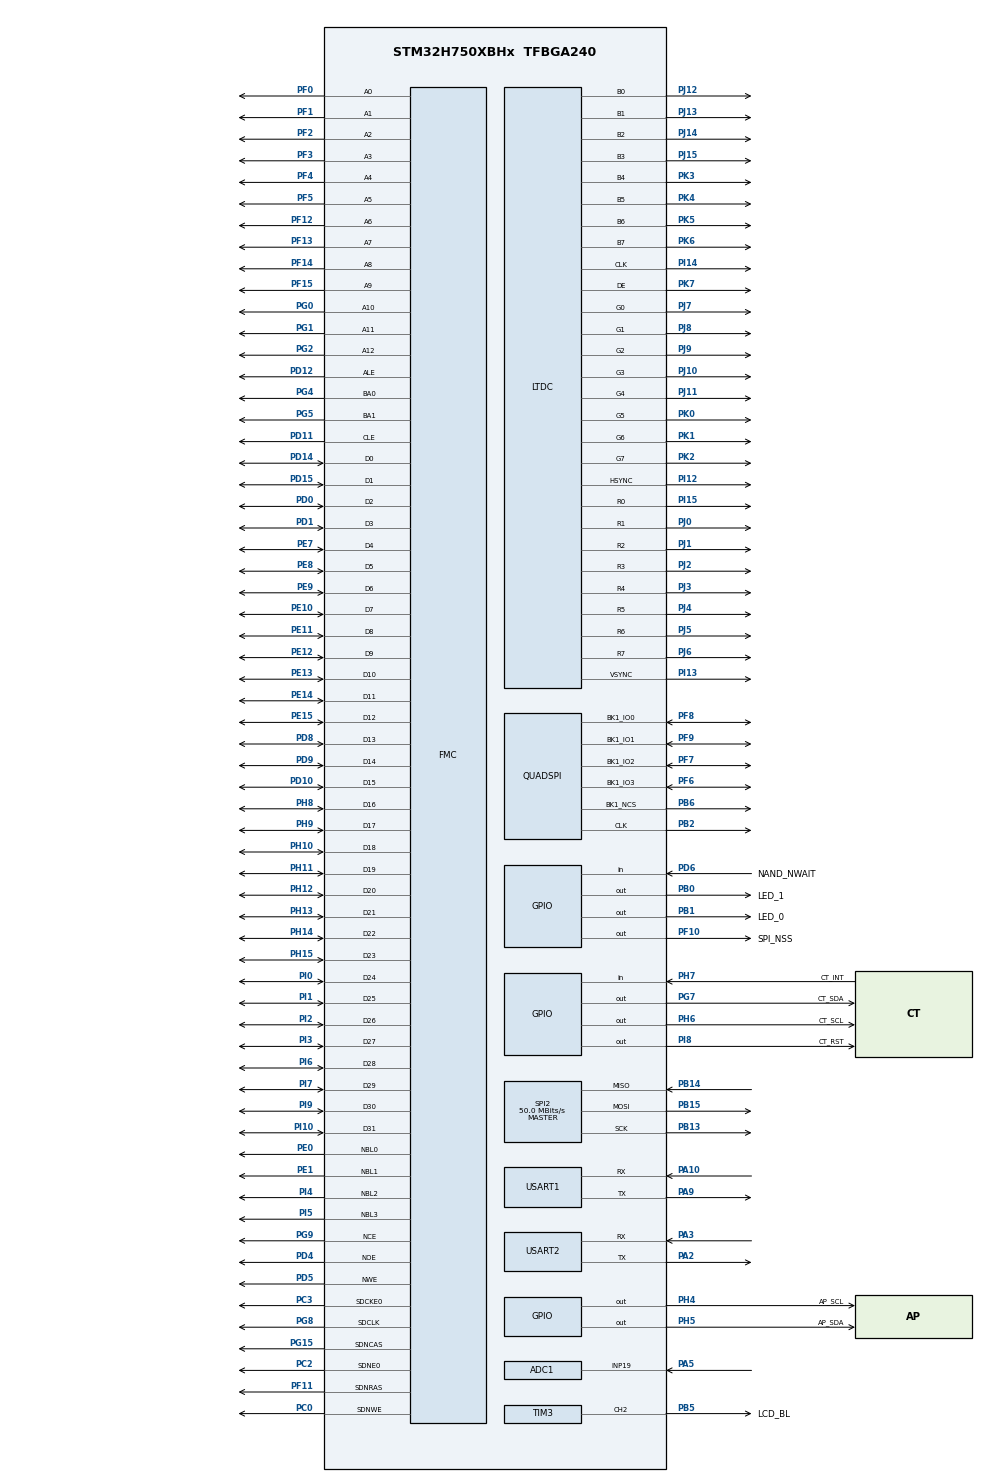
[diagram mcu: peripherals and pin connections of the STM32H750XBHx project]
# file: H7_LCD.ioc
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ADC1.Channel-0\#ChannelRegularConversion=ADC_CHANNEL_19
ADC1.ContinuousConvMode=DISABLE
ADC1.ConversionDataManagement=ADC_CONVERSIONDATA_DR
ADC1.ExternalTrigConv=ADC_SOFTWARE_START
ADC1.NbrOfConversion=1
ADC1.NbrOfConversionFlag=1
ADC1.OffsetNumber-0\#ChannelRegularConversion=ADC_OFFSET_NONE
ADC1.OffsetSignedSaturation-0\#ChannelRegularConversion=DISABLE
ADC1.Overrun=ADC_OVR_DATA_OVERWRITTEN
ADC1.Rank-0\#ChannelRegularConversion=1
ADC1.SamplingTime-0\#ChannelRegularConversion=ADC_SAMPLETIME_387CYCLES_5
ADC1.master=1
CORTEX_M7.CPU_DCache=Enabled
CORTEX_M7.CPU_ICache=Enabled
DMA2D.Mode=DMA2D_M2M
FATFS._CODE_PAGE=936
FATFS._FS_EXFAT=1
FATFS._FS_LOCK=4
FATFS._FS_NORTC=0
FATFS._LFN_UNICODE=0
FATFS._MAX_SS=512
FATFS._USE_CHMOD=1
FATFS._USE_FIND=1
FATFS._USE_LABEL=1
FATFS._USE_LFN=3
FATFS._VOLUMES=1
FMC.AttributeSpaceHiZSetupTime1=10
FMC.AttributeSpaceHoldSetupTime1=10
FMC.AttributeSpaceSetupTime1=10
FMC.AttributeSpaceWaitSetupTime1=10
FMC.CASLatency1=FMC_SDRAM_CAS_LATENCY_2
FMC.ColumnBitsNumber1=FMC_SDRAM_COLUMN_BITS_NUM_9
FMC.CommonSpaceHiZSetupTime1=10
FMC.CommonSpaceHoldSetupTime1=10
FMC.CommonSpaceSetupTime1=10
FMC.CommonSpaceWaitSetupTime1=10
FMC.ECCPageSize1=FMC_NAND_ECC_PAGE_SIZE_512BYTE
FMC.EccComputation1=FMC_NAND_ECC_DISABLE
FMC.ExitSelfRefreshDelay1=8
FMC.LoadToActiveDelay1=2
FMC.NandBlockNbr1=2048
FMC.NandBlockSize1=64
FMC.NandPageSize1=2048
FMC.NandPlaneNbr1=2
FMC.NandPlaneSize1=4096
FMC.NandSpareAreaSize1=64
FMC.RCDDelay1=2
FMC.RPDelay1=2
FMC.ReadBurst1=FMC_SDRAM_RBURST_ENABLE
FMC.RowCycleDelay1=6
FMC.SDClockPeriod1=FMC_SDRAM_CLOCK_PERIOD_2
FMC.SelfRefreshTime1=6
FMC.TARSetupTime1=10
FMC.TCLRSetupTime1=10
FMC.WriteRecoveryTime1=4
LTDC.ActiveH=480
LTDC.ActiveW=800
LTDC.Alpha_L0=255
LTDC.BlendingFactor1_L0=LTDC_BLENDING_FACTOR1_PAxCA
LTDC.BlendingFactor2_L0=LTDC_BLENDING_FACTOR2_PAxCA
LTDC.Blue=0
LTDC.Blue_L0=0
LTDC.FBStartAdress_L0=0xc0000000
LTDC.FBStartAdress_L1=0xc0177001
LTDC.Green_L0=0
LTDC.HBP=88
LTDC.HFP=40
LTDC.HSync=48
LTDC.ImageHeight_L0=480
LTDC.ImageHeight_L1=480
LTDC.ImageWidth_L0=800
LTDC.Layers=0
LTDC.PCPolarity=LTDC_PCPOLARITY_IPC
LTDC.Red=0
LTDC.VBP=32
LTDC.VFP=13
LTDC.VSync=3
LTDC.WindowX1_L0=800
LTDC.WindowX1_L1=800
LTDC.WindowY1_L0=480
LTDC.WindowY1_L1=480
Mcu.Family=STM32H7
Mcu.Name=STM32H750XBHx
Mcu.Package=TFBGA240
NVIC.DMA2D_IRQn=true\:0\:0\:false\:false\:true\:true\:true\:true
NVIC.LTDC_IRQn=true\:0\:0\:false\:false\:true\:true\:true\:true
NVIC.PriorityGroup=NVIC_PRIORITYGROUP_4
NVIC.TIM3_IRQn=true\:1\:0\:true\:false\:true\:true\:true\:true
NVIC.TIM7_IRQn=true\:0\:0\:false\:false\:true\:true\:true\:true
NVIC.USART2_IRQn=true\:0\:0\:false\:false\:true\:true\:true\:true
PA10.GPIO_Speed=GPIO_SPEED_FREQ_LOW
PA10.Mode=Asynchronous
PA10.PinAttribute=Free
PA10.Signal=USART1_RX
PA13\ (JTMS/SWDIO).Mode=Serial_Wire
PA13\ (JTMS/SWDIO).PinAttribute=Free
PA13\ (JTMS/SWDIO).Signal=DEBUG_JTMS-SWDIO
PA14\ (JTCK/SWCLK).Mode=Serial_Wire
PA14\ (JTCK/SWCLK).PinAttribute=Free
PA14\ (JTCK/SWCLK).Signal=DEBUG_JTCK-SWCLK
PA2.GPIO_Speed=GPIO_SPEED_FREQ_LOW
PA2.Mode=Asynchronous
PA2.PinAttribute=Free
PA2.Signal=USART2_TX
PA3.GPIO_Speed=GPIO_SPEED_FREQ_LOW
PA3.Mode=Asynchronous
PA3.Signal=USART2_RX
PA5.Signal=ADCx_INP19
PA9.GPIO_PuPd=GPIO_NOPULL
PA9.GPIO_Speed=GPIO_SPEED_FREQ_LOW
PA9.Mode=Asynchronous
PA9.PinAttribute=Free
PA9.Signal=USART1_TX
PB0.GPIO_Label=LED_1
PB0.GPIO_PuPd=GPIO_PULLUP
PB0.PinState=GPIO_PIN_SET
PB0.Signal=GPIO_Output
PB1.GPIO_Label=LED_0
PB1.GPIO_PuPd=GPIO_PULLUP
PB1.PinState=GPIO_PIN_SET
PB1.Signal=GPIO_Output
PB13.GPIO_Speed=GPIO_SPEED_FREQ_HIGH
PB13.Mode=Full_Duplex_Master
PB13.Signal=SPI2_SCK
PB14.GPIO_Speed=GPIO_SPEED_FREQ_HIGH
PB14.Mode=Full_Duplex_Master
PB14.Signal=SPI2_MISO
PB15.GPIO_Speed=GPIO_SPEED_FREQ_HIGH
PB15.Mode=Full_Duplex_Master
PB15.Signal=SPI2_MOSI
PB2.GPIO_PuPd=GPIO_PULLUP
PB2.GPIO_Speed=GPIO_SPEED_FREQ_HIGH
PB2.Mode=Single Bank 1
PB2.PinAttribute=Free
PB2.Signal=QUADSPI_CLK
PB5.GPIO_Label=LCD_BL
PB5.GPIO_PuPd=GPIO_PULLUP
PB5.GPIO_Speed=GPIO_SPEED_FREQ_LOW
PB5.Signal=S_TIM3_CH2
PB6.GPIO_FM6=__NULL
PB6.GPIO_PuPd=GPIO_PULLUP
PB6.GPIO_Speed=GPIO_SPEED_FREQ_HIGH
PB6.Mode=Single Bank 1
PB6.PinAttribute=Free
PB6.Signal=QUADSPI_BK1_NCS
PC0.GPIO_PuPd=GPIO_PULLUP
PC0.PinAttribute=Free
PC0.Signal=FMC_SDNWE
PC14-OSC32_IN\ (OSC32_IN).Mode=LSE-External-Oscillator
PC14-OSC32_IN\ (OSC32_IN).PinAttribute=Free
PC14-OSC32_IN\ (OSC32_IN).Signal=RCC_OSC32_IN
PC15-OSC32_OUT\ (OSC32_OUT).Mode=LSE-External-Oscillator
PC15-OSC32_OUT\ (OSC32_OUT).PinAttribute=Free
PC15-OSC32_OUT\ (OSC32_OUT).Signal=RCC_OSC32_OUT
PC2.GPIO_PuPd=GPIO_PULLUP
PC2.Mode=SdramChipSelect1_1
PC2.PinAttribute=Free
PC2.Signal=FMC_SDNE0
PC3.GPIO_PuPd=GPIO_PULLUP
PC3.Mode=SdramChipSelect1_1
PC3.PinAttribute=Free
PC3.Signal=FMC_SDCKE0
PD0.PinAttribute=Free
PD0.Signal=FMC_D2_DA2
PD1.PinAttribute=Free
PD1.Signal=FMC_D3_DA3
PD10.Signal=FMC_D15_DA15
PD11.Signal=FMC_A16_CLE
PD12.Signal=FMC_A17_ALE
PD14.Signal=FMC_D0_DA0
PD15.Signal=FMC_D1_DA1
PD4.PinAttribute=Free
PD4.Signal=FMC_NOE
PD5.PinAttribute=Free
PD5.Signal=FMC_NWE
PD6.GPIO_Label=NAND_NWAIT
PD6.GPIO_PuPd=GPIO_PULLUP
PD6.Signal=GPIO_Input
PD8.Signal=FMC_D13_DA13
PD9.Signal=FMC_D14_DA14
PE0.PinAttribute=Free
PE0.Signal=FMC_NBL0
PE1.PinAttribute=Free
PE1.Signal=FMC_NBL1
PE10.PinAttribute=Free
PE10.Signal=FMC_D7_DA7
PE11.PinAttribute=Free
PE11.Signal=FMC_D8_DA8
PE12.PinAttribute=Free
PE12.Signal=FMC_D9_DA9
PE13.Signal=FMC_D10_DA10
PE14.Signal=FMC_D11_DA11
PE15.PinAttribute=Free
PE15.Signal=FMC_D12_DA12
PE7.Signal=FMC_D4_DA4
PE8.Signal=FMC_D5_DA5
PE9.PinAttribute=Free
PE9.Signal=FMC_D6_DA6
PF0.Signal=FMC_A0
PF1.Signal=FMC_A1
PF10.GPIO_Label=SPI_NSS
PF10.GPIO_PuPd=GPIO_PULLUP
PF10.GPIO_Speed=GPIO_SPEED_FREQ_HIGH
PF10.PinAttribute=Free
PF10.PinState=GPIO_PIN_SET
PF10.Signal=GPIO_Output
PF11.Signal=FMC_SDNRAS
PF12.PinAttribute=Free
PF12.Signal=FMC_A6
PF13.PinAttribute=Free
PF13.Signal=FMC_A7
PF14.PinAttribute=Free
PF14.Signal=FMC_A8
PF15.PinAttribute=Free
PF15.Signal=FMC_A9
PF2.Signal=FMC_A2
PF3.PinAttribute=Free
PF3.Signal=FMC_A3
PF4.PinAttribute=Free
PF4.Signal=FMC_A4
PF5.PinAttribute=Free
PF5.Signal=FMC_A5
PF6.GPIO_Speed=GPIO_SPEED_FREQ_HIGH
PF6.Mode=Single Bank 1
PF6.PinAttribute=Free
PF6.Signal=QUADSPI_BK1_IO3
PF7.GPIO_Speed=GPIO_SPEED_FREQ_HIGH
PF7.Mode=Single Bank 1
PF7.PinAttribute=Free
PF7.Signal=QUADSPI_BK1_IO2
PF8.GPIO_Speed=GPIO_SPEED_FREQ_HIGH
PF8.Mode=Single Bank 1
PF8.PinAttribute=Free
PF8.Signal=QUADSPI_BK1_IO0
PF9.GPIO_Speed=GPIO_SPEED_FREQ_HIGH
PF9.Mode=Single Bank 1
PF9.PinAttribute=Free
PF9.Signal=QUADSPI_BK1_IO1
PG0.Signal=FMC_A10
PG1.Signal=FMC_A11
PG15.PinAttribute=Free
PG15.Signal=FMC_SDNCAS
PG2.PinAttribute=Free
PG2.Signal=FMC_A12
PG4.PinAttribute=Free
PG4.Signal=FMC_A14_BA0
PG5.Signal=FMC_A15_BA1
PG7.GPIO_Label=CT_SDA
PG7.GPIO_ModeDefaultOutputPP=GPIO_MODE_OUTPUT_OD
PG7.GPIO_PuPd=GPIO_PULLUP
PG7.GPIO_Speed=GPIO_SPEED_FREQ_LOW
PG7.Signal=GPIO_Output
PG8.Signal=FMC_SDCLK
PG9.Mode=NandChipSelect3_1
PG9.PinAttribute=Free
PG9.Signal=FMC_NCE
PH0-OSC_IN\ (PH0).Mode=HSE-External-Oscillator
PH0-OSC_IN\ (PH0).PinAttribute=Free
PH0-OSC_IN\ (PH0).Signal=RCC_OSC_IN
PH1-OSC_OUT\ (PH1).Mode=HSE-External-Oscillator
PH1-OSC_OUT\ (PH1).PinAttribute=Free
PH1-OSC_OUT\ (PH1).Signal=RCC_OSC_OUT
PH10.Signal=FMC_D18
PH11.Signal=FMC_D19
PH12.PinAttribute=Free
PH12.Signal=FMC_D20
PH13.Signal=FMC_D21
PH14.PinAttribute=Free
PH14.Signal=FMC_D22
PH15.PinAttribute=Free
PH15.Signal=FMC_D23
PH4.GPIO_Label=AP_SCL
PH4.GPIO_PuPd=GPIO_PULLUP
PH4.Signal=GPIO_Output
PH5.GPIO_Label=AP_SDA
PH5.GPIO_PuPd=GPIO_PULLUP
PH5.Signal=GPIO_Output
PH6.GPIO_Label=CT_SCL
PH6.GPIO_ModeDefaultOutputPP=GPIO_MODE_OUTPUT_OD
PH6.GPIO_PuPd=GPIO_PULLUP
PH6.GPIO_Speed=GPIO_SPEED_FREQ_LOW
PH6.Signal=GPIO_Output
PH7.GPIO_Label=CT_INT
PH7.GPIO_PuPd=GPIO_PULLUP
PH7.Signal=GPIO_Input
PH8.Signal=FMC_D16
PH9.PinAttribute=Free
PH9.Signal=FMC_D17
PI0.PinAttribute=Free
PI0.Signal=FMC_D24
PI1.PinAttribute=Free
PI1.Signal=FMC_D25
PI10.PinAttribute=Free
PI10.Signal=FMC_D31
PI12.GPIO_Speed=GPIO_SPEED_FREQ_MEDIUM
PI12.Mode=RGB888
PI12.Signal=LTDC_HSYNC
PI13.GPIO_Speed=GPIO_SPEED_FREQ_MEDIUM
PI13.Mode=RGB888
PI13.Signal=LTDC_VSYNC
PI14.GPIO_Speed=GPIO_SPEED_FREQ_MEDIUM
PI14.Mode=RGB888
PI14.PinAttribute=Free
PI14.Signal=LTDC_CLK
PI15.GPIO_Speed=GPIO_SPEED_FREQ_MEDIUM
PI15.Mode=RGB888
PI15.PinAttribute=Free
PI15.Signal=LTDC_R0
PI2.PinAttribute=Free
PI2.Signal=FMC_D26
PI3.PinAttribute=Free
PI3.Signal=FMC_D27
PI4.Signal=FMC_NBL2
PI5.Signal=FMC_NBL3
PI6.Signal=FMC_D28
PI7.PinAttribute=Free
PI7.Signal=FMC_D29
PI8.GPIO_Label=CT_RST
PI8.GPIO_PuPd=GPIO_PULLUP
PI8.PinAttribute=Free
PI8.Signal=GPIO_Output
PI9.PinAttribute=Free
PI9.Signal=FMC_D30
PJ0.GPIO_Speed=GPIO_SPEED_FREQ_MEDIUM
PJ0.Mode=RGB888
PJ0.PinAttribute=Free
PJ0.Signal=LTDC_R1
PJ1.GPIO_Speed=GPIO_SPEED_FREQ_MEDIUM
PJ1.Mode=RGB888
PJ1.PinAttribute=Free
PJ1.Signal=LTDC_R2
PJ10.GPIO_Speed=GPIO_SPEED_FREQ_MEDIUM
PJ10.Mode=RGB888
PJ10.PinAttribute=Free
PJ10.Signal=LTDC_G3
PJ11.GPIO_Speed=GPIO_SPEED_FREQ_MEDIUM
PJ11.Mode=RGB888
PJ11.PinAttribute=Free
PJ11.Signal=LTDC_G4
PJ12.GPIO_Speed=GPIO_SPEED_FREQ_MEDIUM
PJ12.Mode=RGB888
PJ12.PinAttribute=Free
PJ12.Signal=LTDC_B0
PJ13.GPIO_Speed=GPIO_SPEED_FREQ_MEDIUM
PJ13.Mode=RGB888
PJ13.PinAttribute=Free
PJ13.Signal=LTDC_B1
PJ14.GPIO_Speed=GPIO_SPEED_FREQ_MEDIUM
PJ14.Mode=RGB888
PJ14.PinAttribute=Free
PJ14.Signal=LTDC_B2
PJ15.GPIO_Speed=GPIO_SPEED_FREQ_MEDIUM
PJ15.Mode=RGB888
PJ15.PinAttribute=Free
PJ15.Signal=LTDC_B3
PJ2.GPIO_Speed=GPIO_SPEED_FREQ_MEDIUM
PJ2.Mode=RGB888
PJ2.Signal=LTDC_R3
PJ3.GPIO_Speed=GPIO_SPEED_FREQ_MEDIUM
PJ3.Mode=RGB888
PJ3.Signal=LTDC_R4
PJ4.GPIO_Speed=GPIO_SPEED_FREQ_MEDIUM
PJ4.Mode=RGB888
PJ4.Signal=LTDC_R5
PJ5.GPIO_Speed=GPIO_SPEED_FREQ_MEDIUM
PJ5.Mode=RGB888
PJ5.PinAttribute=Free
PJ5.Signal=LTDC_R6
PJ6.GPIO_Speed=GPIO_SPEED_FREQ_MEDIUM
PJ6.Mode=RGB888
PJ6.PinAttribute=Free
PJ6.Signal=LTDC_R7
PJ7.GPIO_Speed=GPIO_SPEED_FREQ_MEDIUM
PJ7.Mode=RGB888
PJ7.PinAttribute=Free
PJ7.Signal=LTDC_G0
PJ8.GPIO_Speed=GPIO_SPEED_FREQ_MEDIUM
PJ8.Mode=RGB888
PJ8.PinAttribute=Free
PJ8.Signal=LTDC_G1
PJ9.GPIO_Speed=GPIO_SPEED_FREQ_MEDIUM
PJ9.Mode=RGB888
PJ9.PinAttribute=Free
PJ9.Signal=LTDC_G2
PK0.GPIO_Speed=GPIO_SPEED_FREQ_MEDIUM
PK0.Mode=RGB888
PK0.Signal=LTDC_G5
PK1.GPIO_Speed=GPIO_SPEED_FREQ_MEDIUM
PK1.Mode=RGB888
PK1.PinAttribute=Free
PK1.Signal=LTDC_G6
PK2.GPIO_Speed=GPIO_SPEED_FREQ_MEDIUM
PK2.Mode=RGB888
PK2.PinAttribute=Free
PK2.Signal=LTDC_G7
PK3.GPIO_Speed=GPIO_SPEED_FREQ_MEDIUM
PK3.Mode=RGB888
PK3.PinAttribute=Free
PK3.Signal=LTDC_B4
PK4.GPIO_Speed=GPIO_SPEED_FREQ_MEDIUM
PK4.Mode=RGB888
PK4.PinAttribute=Free
PK4.Signal=LTDC_B5
PK5.GPIO_Speed=GPIO_SPEED_FREQ_MEDIUM
PK5.Mode=RGB888
PK5.PinAttribute=Free
PK5.Signal=LTDC_B6
PK6.GPIO_Speed=GPIO_SPEED_FREQ_MEDIUM
PK6.Mode=RGB888
PK6.PinAttribute=Free
PK6.Signal=LTDC_B7
PK7.GPIO_Speed=GPIO_SPEED_FREQ_MEDIUM
PK7.Mode=RGB888
PK7.PinAttribute=Free
PK7.Signal=LTDC_DE
ProjectManager.HeapSize=0x2500
ProjectManager.StackSize=0x2500
ProjectManager.TargetToolchain=Makefile
QUADSPI.ChipSelectHighTime=QSPI_CS_HIGH_TIME_5_CYCLE
QUADSPI.ClockMode=QSPI_CLOCK_MODE_0
QUADSPI.ClockPrescaler=2-1
QUADSPI.FifoThreshold=16
QUADSPI.FlashSize=23-1
QUADSPI.SampleShifting=QSPI_SAMPLE_SHIFTING_HALFCYCLE
RCC.ADCCLockSelection=RCC_ADCCLKSOURCE_PLL3
RCC.ADCFreq_Value=33333333.333333332
RCC.APB1Freq_Value=75000000
RCC.APB2Freq_Value=75000000
RCC.APB3Freq_Value=75000000
RCC.APB4Freq_Value=75000000
RCC.CECCLockSelection=RCC_CECCLKSOURCE_LSI
RCC.CKPERSourceSelection=RCC_CLKPSOURCE_HSE
RCC.CSI_VALUE=4000000
RCC.CortexFreq_Value=300000000
RCC.Cortex_DivARG=SystemCoreClock/1000
RCC.D1PPRE=RCC_APB3_DIV2
RCC.D2PPRE1=RCC_APB1_DIV2
RCC.D2PPRE2=RCC_APB2_DIV2
RCC.D3PPRE=RCC_APB4_DIV2
RCC.DFSDMCLockSelection=RCC_DFSDM1CLKSOURCE_D2PCLK1
RCC.DIVM1=2
RCC.DIVM2=2
RCC.DIVM3=2
RCC.DIVN1=48
RCC.DIVN2=16
RCC.DIVN3=24
RCC.DIVP2=4
RCC.DIVP3=3
RCC.DIVQ1=3
RCC.DIVQ2=1
RCC.DIVQ3=10
RCC.DIVR3=9
RCC.DSICLockSelection=RCC_DSICLKSOURCE_PHY
RCC.DSIPHY_Div=8
RCC.DSITX_Div=4
RCC.DSI_PHY_VALUE=12288000
RCC.EXTERNAL_CLOCK_VALUE=12288000
RCC.FDCANCLockSelection=RCC_FDCANCLKSOURCE_PLL
RCC.FMCCLockSelection=RCC_FMCCLKSOURCE_PLL
RCC.HCLKFreq_Value=150000000
RCC.HPRE=RCC_HCLK_DIV2
RCC.HSE_VALUE=25000000
RCC.HSI_VALUE=64000000
RCC.I2C123CLockSelection=RCC_I2C123CLKSOURCE_D2PCLK1
RCC.I2C4CLockSelection=RCC_I2C4CLKSOURCE_D3PCLK1
RCC.LPTIM1CLockSelection=RCC_LPTIM1CLKSOURCE_D2PCLK1
RCC.LPTIM2CLockSelection=RCC_LPTIM2CLKSOURCE_D3PCLK1
RCC.LPTIM345CLockSelection=RCC_LPTIM345CLKSOURCE_D3PCLK1
RCC.LPUART1CLockSelection=RCC_LPUART1CLKSOURCE_D3PCLK1
RCC.PLL1_VCI_Range-AdvancedSettings=RCC_PLL1VCIRANGE_0
RCC.PLL2FRACN=0
RCC.PLL3FRACN=0
RCC.PLL3_VCI_Range-AdvancedSettings=RCC_PLL3VCIRANGE_0
RCC.PLLDSIDev=2
RCC.PLLDSIIDF=DSI_PLL_IN_DIV1
RCC.PLLDSIMult=2
RCC.PLLDSINDIV=20
RCC.PLLDSIODF=DSI_PLL_OUT_DIV1
RCC.PLLFRACN=0
RCC.PLLSourceVirtual=RCC_PLLSOURCE_HSE
RCC.PWR_Regulator_Voltage_Scale=PWR_REGULATOR_VOLTAGE_SCALE2
RCC.ProductRev=revV
RCC.RC48_VALUE=48000000
RCC.RCC_MCO1Source=RCC_MCO1SOURCE_HSI
RCC.RCC_MCO2Source=RCC_MCO2SOURCE_SYSCLK
RCC.RCC_RTC_Clock_Source_FROM_HSE=RCC_RTCCLKSOURCE_HSE_DIV50
RCC.RNGCLockSelection=RCC_RNGCLKSOURCE_HSI48
RCC.RTCClockSelection=RCC_RTCCLKSOURCE_LSE
RCC.SAI1CLockSelection=RCC_SAI1CLKSOURCE_PLL
RCC.SAI23CLockSelection=RCC_SAI23CLKSOURCE_PLL
RCC.SAI4ACLockSelection=RCC_SAI4ACLKSOURCE_PLL
RCC.SAI4BCLockSelection=RCC_SAI4BCLKSOURCE_PLL
RCC.SDMMC1CLockSelection=RCC_SDMMCCLKSOURCE_PLL2
RCC.SPDIFCLockSelection=RCC_SPDIFRXCLKSOURCE_PLL
RCC.SPI123CLockSelection=RCC_SPI123CLKSOURCE_PLL3
RCC.SPI6CLockSelection=RCC_SPI6CLKSOURCE_D3PCLK1
RCC.SWPCLockSelection=RCC_SWPMI1CLKSOURCE_D2PCLK1
RCC.SYSCLKFreq_VALUE=300000000
RCC.SYSCLKSource=RCC_SYSCLKSOURCE_PLLCLK
RCC.Spi45ClockSelection=RCC_SPI45CLKSOURCE_D2PCLK1
RCC.USART16CLockSelection=RCC_USART16CLKSOURCE_PLL3
RCC.USART234578CLockSelection=RCC_USART234578CLKSOURCE_PLL3
RCC.USBCLockSelection=RCC_USBCLKSOURCE_PLL
RCC.USBFreq_Value=200000000
RTC.Date=2
RTC.Format=RTC_FORMAT_BIN
RTC.Hours=19
RTC.Minutes=28
RTC.Month=RTC_MONTH_NOVEMBER
RTC.WeekDay=RTC_WEEKDAY_WEDNESDAY
RTC.Year=22
SH.ADCx_INP19.0=ADC1_INP19,IN19-Single-Ended
SH.FMC_A0.0=FMC_A0,13b-sda1
SH.FMC_A1.0=FMC_A1,13b-sda1
SH.FMC_A10.0=FMC_A10,13b-sda1
SH.FMC_A11.0=FMC_A11,13b-sda1
SH.FMC_A12.0=FMC_A12,13b-sda1
SH.FMC_A14_BA0.0=FMC_BA0,FourSdramBanks1
SH.FMC_A15_BA1.0=FMC_BA1,FourSdramBanks1
SH.FMC_A16_CLE.0=FMC_CLE,8b-dmux1
SH.FMC_A17_ALE.0=FMC_ALE,8b-dmux1
SH.FMC_A2.0=FMC_A2,13b-sda1
SH.FMC_A3.0=FMC_A3,13b-sda1
SH.FMC_A4.0=FMC_A4,13b-sda1
SH.FMC_A5.0=FMC_A5,13b-sda1
SH.FMC_A6.0=FMC_A6,13b-sda1
SH.FMC_A7.0=FMC_A7,13b-sda1
SH.FMC_A8.0=FMC_A8,13b-sda1
SH.FMC_A9.0=FMC_A9,13b-sda1
SH.FMC_D0_DA0.0=FMC_D0,sd-32b-d1
SH.FMC_D0_DA0.1=FMC_D0,8b-dmux1
SH.FMC_D10_DA10.0=FMC_D10,sd-32b-d1
SH.FMC_D11_DA11.0=FMC_D11,sd-32b-d1
SH.FMC_D12_DA12.0=FMC_D12,sd-32b-d1
SH.FMC_D13_DA13.0=FMC_D13,sd-32b-d1
SH.FMC_D14_DA14.0=FMC_D14,sd-32b-d1
SH.FMC_D15_DA15.0=FMC_D15,sd-32b-d1
SH.FMC_D16.0=FMC_D16,sd-32b-d1
SH.FMC_D17.0=FMC_D17,sd-32b-d1
SH.FMC_D18.0=FMC_D18,sd-32b-d1
SH.FMC_D19.0=FMC_D19,sd-32b-d1
SH.FMC_D1_DA1.0=FMC_D1,sd-32b-d1
SH.FMC_D1_DA1.1=FMC_D1,8b-dmux1
SH.FMC_D20.0=FMC_D20,sd-32b-d1
SH.FMC_D21.0=FMC_D21,sd-32b-d1
SH.FMC_D22.0=FMC_D22,sd-32b-d1
SH.FMC_D23.0=FMC_D23,sd-32b-d1
SH.FMC_D24.0=FMC_D24,sd-32b-d1
SH.FMC_D25.0=FMC_D25,sd-32b-d1
SH.FMC_D26.0=FMC_D26,sd-32b-d1
SH.FMC_D27.0=FMC_D27,sd-32b-d1
SH.FMC_D28.0=FMC_D28,sd-32b-d1
SH.FMC_D29.0=FMC_D29,sd-32b-d1
SH.FMC_D2_DA2.0=FMC_D2,sd-32b-d1
SH.FMC_D2_DA2.1=FMC_D2,8b-dmux1
SH.FMC_D30.0=FMC_D30,sd-32b-d1
SH.FMC_D31.0=FMC_D31,sd-32b-d1
SH.FMC_D3_DA3.0=FMC_D3,sd-32b-d1
SH.FMC_D3_DA3.1=FMC_D3,8b-dmux1
SH.FMC_D4_DA4.0=FMC_D4,sd-32b-d1
SH.FMC_D4_DA4.1=FMC_D4,8b-dmux1
SH.FMC_D5_DA5.0=FMC_D5,sd-32b-d1
SH.FMC_D5_DA5.1=FMC_D5,8b-dmux1
SH.FMC_D6_DA6.0=FMC_D6,sd-32b-d1
SH.FMC_D6_DA6.1=FMC_D6,8b-dmux1
SH.FMC_D7_DA7.0=FMC_D7,sd-32b-d1
SH.FMC_D7_DA7.1=FMC_D7,8b-dmux1
SH.FMC_D8_DA8.0=FMC_D8,sd-32b-d1
SH.FMC_D9_DA9.0=FMC_D9,sd-32b-d1
SH.FMC_NBL0.0=FMC_NBL0,Sd4ByteEnable1
SH.FMC_NBL1.0=FMC_NBL1,Sd4ByteEnable1
SH.FMC_NBL2.0=FMC_NBL2,Sd4ByteEnable1
SH.FMC_NBL3.0=FMC_NBL3,Sd4ByteEnable1
SH.FMC_NOE.0=FMC_NOE,8b-dmux1
SH.FMC_NWE.0=FMC_NWE,8b-dmux1
SH.FMC_SDCLK.0=FMC_SDCLK,13b-sda1
SH.FMC_SDNCAS.0=FMC_SDNCAS,13b-sda1
SH.FMC_SDNRAS.0=FMC_SDNRAS,13b-sda1
SH.FMC_SDNWE.0=FMC_SDNWE,13b-sda1
SH.S_TIM3_CH2.0=TIM3_CH2,PWM Generation2 CH2
SPI2.BaudRatePrescaler=SPI_BAUDRATEPRESCALER_2
SPI2.CLKPhase=SPI_PHASE_2EDGE
SPI2.CLKPolarity=SPI_POLARITY_HIGH
SPI2.CalculateBaudRate=50.0 MBits/s
SPI2.DataSize=SPI_DATASIZE_8BIT
SPI2.Direction=SPI_DIRECTION_2LINES
SPI2.Mode=SPI_MODE_MASTER
SPI2.NSSPolarity=SPI_NSS_POLARITY_LOW
SPI2.VirtualType=VM_MASTER
TIM3.AutoReloadPreload=TIM_AUTORELOAD_PRELOAD_ENABLE
TIM3.Channel-PWM\ Generation2\ CH2=TIM_CHANNEL_2
TIM3.OCPolarity_2=TIM_OCPOLARITY_HIGH
TIM3.Period=499
TIM3.Prescaler=149
TIM6.Prescaler=149
TIM7.AutoReloadPreload=TIM_AUTORELOAD_PRELOAD_ENABLE
TIM7.Period=4999
TIM7.Prescaler=149
USART1.FIFOMode=FIFOMODE_ENABLE
USART1.VirtualMode-Asynchronous=VM_ASYNC
USART2.VirtualMode-Asynchronous=VM_ASYNC
VP_DMA2D_VS_DMA2D.Mode=DMA2D_Activate
VP_FATFS_VS_Generic.Mode=User_defined
VP_RTC_VS_RTC_Activate.Mode=RTC_Enabled
VP_RTC_VS_RTC_Calendar.Mode=RTC_Calendar
VP_TIM3_VS_ClockSourceINT.Mode=Internal
VP_TIM6_VS_ClockSourceINT.Mode=Enable_Timer
VP_TIM7_VS_ClockSourceINT.Mode=Enable_Timer
board=custom

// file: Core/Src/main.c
/* USER CODE BEGIN Header */
/**
 ******************************************************************************
 * @file           : main.c
 * @brief          : Main program body
 ******************************************************************************
 * @attention
 *
 * Copyright (c) 2022 STMicroelectronics.
 * All rights reserved.
 *
 * This software is licensed under terms that can be found in the LICENSE file
 * in the root directory of this software component.
 * If no LICENSE file comes with this software, it is provided AS-IS.
 *
 ******************************************************************************
 */
/* USER CODE END Header */
#include "main.h"
#include "adc.h"
#include "dma2d.h"
#include "fatfs.h"
#include "ltdc.h"
#include "rtc.h"
#include "spi.h"
#include "tim.h"
#include "usart.h"
#include "gpio.h"
#include "fmc.h"

/* USER CODE BEGIN Includes */
#include "sdram.h"
#include "norflash.h"
#include "lvgl/lvgl.h"
#include "lvgl_port/lv_port_disp.h"
#include "lvgl_port/lv_port_indev.h"
// #include "lvgl_port/lv_port_fs.h"
#include "demos/lv_demos.h"
#include "touch.h"
#include "nand.h"
#include "malloc.h"
#include "ftl.h"
#include "mpu.h"
#include "ap3216c.h"
// #include "sdmmc_sdcard.h"
#include "gui_dev.h"
#include "gui_battery.h"
#include "generated/gui_guider.h"
#include "custom/custom.h"
/* USER CODE END Includes */

void SystemClock_Config(void);
void PeriphCommonClock_Config(void);

/* USER CODE BEGIN 0 */
lv_ui guider_ui;
/*
static void event_handler(lv_event_t *event)
{
  lv_obj_t *obj = lv_event_get_target(event);
  switch (lv_event_get_code(event))
  {
  case LV_EVENT_PRESSED:
    break;
  case LV_EVENT_RELEASED:

    break;
  case LV_EVENT_VALUE_CHANGED:
    if (strcmp((char *)lv_event_get_user_data(event), "sw1") == 0)
    {
      if (lv_obj_has_state(obj, LV_STATE_CHECKED))
        HAL_GPIO_WritePin(LED_0_GPIO_Port, LED_0_Pin, 0);
      else
        HAL_GPIO_WritePin(LED_0_GPIO_Port, LED_0_Pin, 1);
    }
    else if (strcmp((char *)lv_event_get_user_data(event), "sw2") == 0)
    {
      if (lv_obj_has_state(obj, LV_STATE_CHECKED))
        HAL_GPIO_WritePin(LED_1_GPIO_Port, LED_1_Pin, 0);
      else
        HAL_GPIO_WritePin(LED_1_GPIO_Port, LED_1_Pin, 1);
    }

    break;

  default:
    break;
  }
} */

/* USER CODE END 0 */

int main(void)
{
  /* USER CODE BEGIN 1 */
  SCB->VTOR = QSPI_BASE + 0x3C000; // 设置中断向量表

  /* USER CODE END 1 */

  /* Enable I-Cache---------------------------------------------------------*/
  SCB_EnableICache();

  /* Enable D-Cache---------------------------------------------------------*/
  SCB_EnableDCache();

  /* MCU Configuration--------------------------------------------------------*/

  /* Reset of all peripherals, Initializes the Flash interface and the Systick. */
  HAL_Init();

  /* Configure the system clock */
  SystemClock_Config();

  /* Configure the peripherals common clocks */
  PeriphCommonClock_Config();

  /* USER CODE BEGIN SysInit */
  // NAND_IDTypeDef id;
  // NAND_AddressTypeDef temp;

  /* USER CODE END SysInit */

  /* Initialize all configured peripherals */
  MX_GPIO_Init();
  MX_TIM6_Init(); // 延时函数delay用计时器
  MX_TIM7_Init(); // lvgl tick用计时器
  MX_USART1_UART_Init();
  MX_USART2_UART_Init();
  MX_RTC_Init();
  MX_SPI2_Init();
  MX_DMA2D_Init();
  MX_FMC_Init();
  MX_LTDC_Init();
  MX_FATFS_Init();
  MX_TIM3_Init(); // 调光PWM用计时器
  MX_ADC1_Init();
  /* USER CODE BEGIN 2 */
  __enable_irq();
  my_mem_init(SRAMIN);
  my_mem_init(SRAMEX);
  printf("Jump in ex_flash!\n");
  // MPU_Memory_Protection();
  AP3216C_Init();
  HAL_TIM_PWM_Start(&htim3, TIM_CHANNEL_2); // PWM 频率 2KHz
  __HAL_TIM_SetCompare(&htim3, TIM_CHANNEL_2, 500);
  lv_init();
  lv_port_disp_init();
  lv_port_indev_init();

  // lv_port_fs_init();
  // lv_disp_set_rotation(NULL, LV_DISP_ROT_90);
  // lvgl_clock_start();

  setup_ui(&guider_ui);
  lvgl_first_demo_start();
  draw_battery();
  custom_init(&guider_ui);
  // lv_demo_widgets();
  // lv_demo_benchmark();
  //   lv_demo_stress();
  // lv_demo_music();
  /* USER CODE END 2 */

  /* Infinite loop */
  /* USER CODE BEGIN WHILE */
  int ap_count = 0;
  u8 pwm_factor = 0;
  u16 als, ir, ps;
  int bl_lumi = 500;
  int bl_lumi_count = 500;
  u8 adc_factor = 0;
  u8 adc_out = 0;
  float adc_sample = 0.0;
  while (1)
  {
    tp_dev.scan(0);
    lv_task_handler();
    delay_ms(4); // 给4ms延时，是考虑循环里的其他任务，给lv_task差不多5ms间隔

    if (ap_count == 500) // 每2秒读一次环境光数值   500 × 4ms
    {
      AP3216C_ReadData(&ir, &ps, &als); // als读取值范围 0～65536
      if (als >= 100 || als <= 4100)    // PWM最低占空比20%（100/500）
        bl_lumi = als / 10 + 90;
      if (als < 100)
        bl_lumi = 100;
      if (als > 4100)
        bl_lumi = 500;
      ap_count = 0;
    }
    else
      ap_count++;

    if (pwm_factor == 2) // 每8ms PWM占空比调整1/500
    {
      if (bl_lumi_count > bl_lumi)
      {
        bl_lumi_count--;
        __HAL_TIM_SetCompare(&htim3, TIM_CHANNEL_2, bl_lumi_count);
      }
      else if (bl_lumi_count < bl_lumi)
      {
        bl_lumi_count++;
        __HAL_TIM_SetCompare(&htim3, TIM_CHANNEL_2, bl_lumi_count);
      }
      else
      {
      }
      pwm_factor = 0;
    }
    else
      pwm_factor++;

    if (adc_factor == 240) // 约1s一次电压采样
    {
      adc_sample += Get_Adc();
      adc_factor = 0;
      adc_out++;
    }
    else
    {
      adc_factor++;
    }
    if (adc_out == 15) // 采样15次输出一次电压平均值，约15秒输出一次电压平均值
    {
      printf("volt : %.3f v\n", adc_sample / adc_out);
      adc_out = 0;
      adc_sample = 0;
    }
    /* USER CODE END WHILE */

  }
}

void SystemClock_Config(void)
{
  RCC_OscInitTypeDef RCC_OscInitStruct = {0};
  RCC_ClkInitTypeDef RCC_ClkInitStruct = {0};

  /** Supply configuration update enable
   */
  HAL_PWREx_ConfigSupply(PWR_LDO_SUPPLY);

  /** Configure the main internal regulator output voltage
   */
  __HAL_PWR_VOLTAGESCALING_CONFIG(PWR_REGULATOR_VOLTAGE_SCALE2);

  while (!__HAL_PWR_GET_FLAG(PWR_FLAG_VOSRDY))
  {
  }

  /** Configure LSE Drive Capability
   */
  HAL_PWR_EnableBkUpAccess();
  __HAL_RCC_LSEDRIVE_CONFIG(RCC_LSEDRIVE_LOW);

  /** Macro to configure the PLL clock source
   */
  __HAL_RCC_PLL_PLLSOURCE_CONFIG(RCC_PLLSOURCE_HSE);

  /** Initializes the RCC Oscillators according to the specified parameters
   * in the RCC_OscInitTypeDef structure.
   */
  RCC_OscInitStruct.OscillatorType = RCC_OSCILLATORTYPE_HSE | RCC_OSCILLATORTYPE_LSE;
  RCC_OscInitStruct.HSEState = RCC_HSE_ON;
  RCC_OscInitStruct.LSEState = RCC_LSE_ON;
  RCC_OscInitStruct.PLL.PLLState = RCC_PLL_ON;
  RCC_OscInitStruct.PLL.PLLSource = RCC_PLLSOURCE_HSE;
  RCC_OscInitStruct.PLL.PLLM = 2;
  RCC_OscInitStruct.PLL.PLLN = 48;
  RCC_OscInitStruct.PLL.PLLP = 2;
  RCC_OscInitStruct.PLL.PLLQ = 3;
  RCC_OscInitStruct.PLL.PLLR = 2;
  RCC_OscInitStruct.PLL.PLLRGE = RCC_PLL1VCIRANGE_3;
  RCC_OscInitStruct.PLL.PLLVCOSEL = RCC_PLL1VCOWIDE;
  RCC_OscInitStruct.PLL.PLLFRACN = 0;
  if (HAL_RCC_OscConfig(&RCC_OscInitStruct) != HAL_OK)
  {
    Error_Handler();
  }

  /** Initializes the CPU, AHB and APB buses clocks
   */
  RCC_ClkInitStruct.ClockType = RCC_CLOCKTYPE_HCLK | RCC_CLOCKTYPE_SYSCLK | RCC_CLOCKTYPE_PCLK1 | RCC_CLOCKTYPE_PCLK2 | RCC_CLOCKTYPE_D3PCLK1 | RCC_CLOCKTYPE_D1PCLK1;
  RCC_ClkInitStruct.SYSCLKSource = RCC_SYSCLKSOURCE_PLLCLK;
  RCC_ClkInitStruct.SYSCLKDivider = RCC_SYSCLK_DIV1;
  RCC_ClkInitStruct.AHBCLKDivider = RCC_HCLK_DIV2;
  RCC_ClkInitStruct.APB3CLKDivider = RCC_APB3_DIV2;
  RCC_ClkInitStruct.APB1CLKDivider = RCC_APB1_DIV2;
  RCC_ClkInitStruct.APB2CLKDivider = RCC_APB2_DIV2;
  RCC_ClkInitStruct.APB4CLKDivider = RCC_APB4_DIV2;

  if (HAL_RCC_ClockConfig(&RCC_ClkInitStruct, FLASH_LATENCY_2) != HAL_OK)
  {
    Error_Handler();
  }
}

void PeriphCommonClock_Config(void)
{
  RCC_PeriphCLKInitTypeDef PeriphClkInitStruct = {0};

  /** Initializes the peripherals clock
   */
  PeriphClkInitStruct.PeriphClockSelection = RCC_PERIPHCLK_ADC | RCC_PERIPHCLK_SPI2 | RCC_PERIPHCLK_USART1 | RCC_PERIPHCLK_USART2 | RCC_PERIPHCLK_LTDC;
  PeriphClkInitStruct.PLL3.PLL3M = 2;
  PeriphClkInitStruct.PLL3.PLL3N = 24;
  PeriphClkInitStruct.PLL3.PLL3P = 3;
  PeriphClkInitStruct.PLL3.PLL3Q = 10;
  PeriphClkInitStruct.PLL3.PLL3R = 9;
  PeriphClkInitStruct.PLL3.PLL3RGE = RCC_PLL3VCIRANGE_3;
  PeriphClkInitStruct.PLL3.PLL3VCOSEL = RCC_PLL3VCOWIDE;
  PeriphClkInitStruct.PLL3.PLL3FRACN = 0;
  PeriphClkInitStruct.Spi123ClockSelection = RCC_SPI123CLKSOURCE_PLL3;
  PeriphClkInitStruct.Usart234578ClockSelection = RCC_USART234578CLKSOURCE_PLL3;
  PeriphClkInitStruct.Usart16ClockSelection = RCC_USART16CLKSOURCE_PLL3;
  PeriphClkInitStruct.AdcClockSelection = RCC_ADCCLKSOURCE_PLL3;
  if (HAL_RCCEx_PeriphCLKConfig(&PeriphClkInitStruct) != HAL_OK)
  {
    Error_Handler();
  }
}

void Error_Handler(void)
{
  /* USER CODE BEGIN Error_Handler_Debug */
  /* User can add his own implementation to report the HAL error return state */
  printf("an error occured!\n");
  __disable_irq();
  while (1)
  {
  }
  /* USER CODE END Error_Handler_Debug */
}
